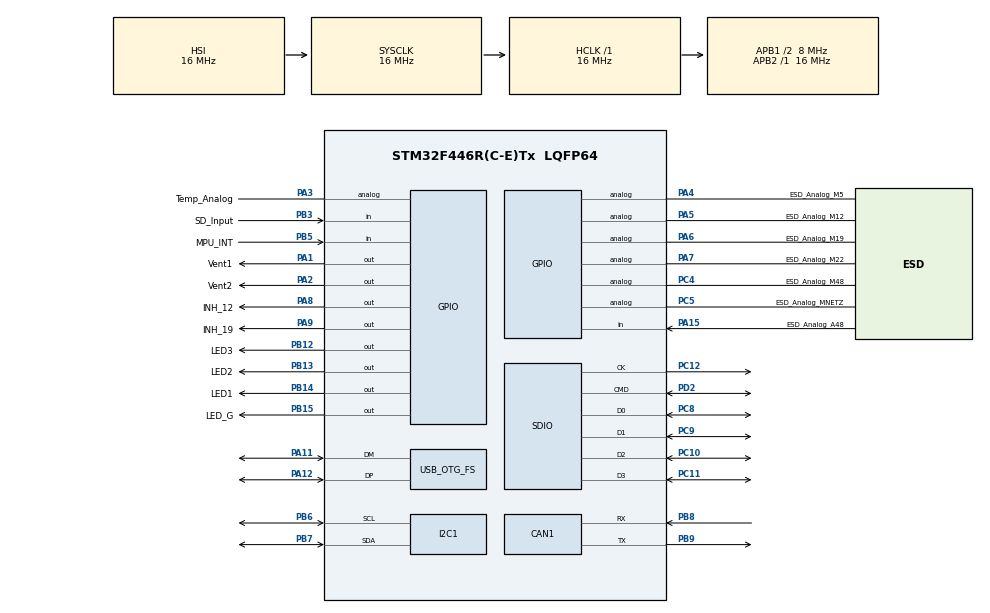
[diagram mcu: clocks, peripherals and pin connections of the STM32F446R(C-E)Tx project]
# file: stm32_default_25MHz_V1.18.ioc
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CAN1.CalculateTimeQuantum=2000.0
Mcu.Family=STM32F4
Mcu.Name=STM32F446R(C-E)Tx
Mcu.Package=LQFP64
NVIC.OTG_FS_IRQn=true\:0\:0\:false\:false\:true\:false\:true
NVIC.PriorityGroup=NVIC_PRIORITYGROUP_4
PA1.GPIO_Label=Vent1
PA1.Signal=GPIO_Output
PA11.Mode=Device_Only
PA11.Signal=USB_OTG_FS_DM
PA12.Mode=Device_Only
PA12.Signal=USB_OTG_FS_DP
PA13.Mode=Serial_Wire
PA13.Signal=SYS_JTMS-SWDIO
PA14.Mode=Serial_Wire
PA14.Signal=SYS_JTCK-SWCLK
PA15.GPIO_Label=ESD_Analog_A48
PA15.Signal=GPIO_Input
PA2.GPIO_Label=Vent2
PA2.Signal=GPIO_Output
PA3.GPIO_Label=Temp_Analog
PA3.Signal=GPIO_Analog
PA4.GPIO_Label=ESD_Analog_M5
PA4.Signal=GPIO_Analog
PA5.GPIO_Label=ESD_Analog_M12
PA5.Signal=GPIO_Analog
PA6.GPIO_Label=ESD_Analog_M19
PA6.Signal=GPIO_Analog
PA7.GPIO_Label=ESD_Analog_M22
PA7.Signal=GPIO_Analog
PA8.GPIO_Label=INH_12
PA8.Signal=GPIO_Output
PA9.GPIO_Label=INH_19
PA9.Signal=GPIO_Output
PB12.GPIO_Label=LED3
PB12.Signal=GPIO_Output
PB13.GPIO_Label=LED2
PB13.Signal=GPIO_Output
PB14.GPIO_Label=LED1
PB14.Signal=GPIO_Output
PB15.GPIO_Label=LED_G
PB15.Signal=GPIO_Output
PB3.GPIO_Label=SD_Input
PB3.Signal=GPIO_Input
PB5.GPIO_Label=MPU_INT
PB5.Signal=GPIO_Input
PB6.Mode=I2C
PB6.Signal=I2C1_SCL
PB7.Mode=I2C
PB7.Signal=I2C1_SDA
PB8.Mode=Master
PB8.Signal=CAN1_RX
PB9.Mode=Master
PB9.Signal=CAN1_TX
PC10.Mode=SD_4_bits_Wide_bus
PC10.Signal=SDIO_D2
PC11.Mode=SD_4_bits_Wide_bus
PC11.Signal=SDIO_D3
PC12.Mode=SD_4_bits_Wide_bus
PC12.Signal=SDIO_CK
PC4.GPIO_Label=ESD_Analog_M48
PC4.Signal=GPIO_Analog
PC5.GPIO_Label=ESD_Analog_MNETZ
PC5.Signal=GPIO_Analog
PC8.Mode=SD_4_bits_Wide_bus
PC8.Signal=SDIO_D0
PC9.Mode=SD_4_bits_Wide_bus
PC9.Signal=SDIO_D1
PD2.Mode=SD_4_bits_Wide_bus
PD2.Signal=SDIO_CMD
PH0-OSC_IN.Mode=HSE-External-Oscillator
PH0-OSC_IN.Signal=RCC_OSC_IN
PH1-OSC_OUT.Mode=HSE-External-Oscillator
PH1-OSC_OUT.Signal=RCC_OSC_OUT
ProjectManager.HeapSize=0x200
ProjectManager.StackSize=0x400
ProjectManager.TargetToolchain=TrueSTUDIO
RCC.AHBFreq_Value=16000000
RCC.APB1CLKDivider=RCC_HCLK_DIV2
RCC.APB1Freq_Value=8000000
RCC.APB1TimFreq_Value=16000000
RCC.APB2Freq_Value=16000000
RCC.APB2TimFreq_Value=16000000
RCC.CortexFreq_Value=16000000
RCC.HCLKFreq_Value=16000000
RCC.HSE_VALUE=25000000
RCC.PLLM=15
RCC.PLLN=144
RCC.PLLQ=5
RCC.SYSCLKFreq_VALUE=16000000
RCC.USBFreq_Value=48000000
RCC.VCOOutputFreq_Value=240000000
USB_DEVICE.CLASS_NAME_FS=CDC
USB_DEVICE.VirtualMode-CDC_FS=Cdc
USB_DEVICE.VirtualModeFS=Cdc_FS
USB_OTG_FS.VirtualMode=Device_Only
VP_USB_DEVICE_VS_USB_DEVICE_CDC_FS.Mode=CDC_FS
board=custom

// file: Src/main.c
/* USER CODE BEGIN Header */
/**
  ******************************************************************************
  * @file           : main.c
  * @brief          : Main program body
  ******************************************************************************
  * @attention
  *
  * <h2><center>&copy; Copyright (c) 2019 STMicroelectronics.
  * All rights reserved.</center></h2>
  *
  * This software component is licensed by ST under BSD 3-Clause license,
  * the "License"; You may not use this file except in compliance with the
  * License. You may obtain a copy of the License at:
  *                        opensource.org/licenses/BSD-3-Clause
  *
  ******************************************************************************
  */
/* USER CODE END Header */

#include "main.h"
#include "can.h"
#include "i2c.h"
#include "sdio.h"
#include "usb_device.h"
#include "gpio.h"

void SystemClock_Config(void);

int main(void)
{

  /* MCU Configuration--------------------------------------------------------*/

  /* Reset of all peripherals, Initializes the Flash interface and the Systick. */
  HAL_Init();

  /* Configure the system clock */
  SystemClock_Config();

  /* Initialize all configured peripherals */
  MX_GPIO_Init();
  MX_CAN1_Init();
  MX_I2C1_Init();
  MX_SDIO_SD_Init();
  MX_USB_DEVICE_Init();
  /* USER CODE BEGIN 2 */

  HAL_GPIO_WritePin(INH_12_GPIO_Port, INH_12_Pin, GPIO_PIN_RESET);
  HAL_GPIO_WritePin(INH_19_GPIO_Port, INH_19_Pin, GPIO_PIN_RESET);
  HAL_GPIO_WritePin(LED_G_GPIO_Port, LED_G_Pin, GPIO_PIN_SET);

  /* USER CODE END 2 */

  /* Infinite loop */
  while (1)
  {

  }
}

void SystemClock_Config(void)
{
  RCC_OscInitTypeDef RCC_OscInitStruct = {0};
  RCC_ClkInitTypeDef RCC_ClkInitStruct = {0};
  RCC_PeriphCLKInitTypeDef PeriphClkInitStruct = {0};

  /** Configure the main internal regulator output voltage
  */
  __HAL_RCC_PWR_CLK_ENABLE();
  __HAL_PWR_VOLTAGESCALING_CONFIG(PWR_REGULATOR_VOLTAGE_SCALE3);
  /** Initializes the CPU, AHB and APB busses clocks
  */
  RCC_OscInitStruct.OscillatorType = RCC_OSCILLATORTYPE_HSI;
  RCC_OscInitStruct.HSIState = RCC_HSI_ON;
  RCC_OscInitStruct.HSICalibrationValue = RCC_HSICALIBRATION_DEFAULT;
  RCC_OscInitStruct.PLL.PLLState = RCC_PLL_ON;
  RCC_OscInitStruct.PLL.PLLSource = RCC_PLLSOURCE_HSE;
  RCC_OscInitStruct.PLL.PLLM = 15;
  RCC_OscInitStruct.PLL.PLLN = 144;
  RCC_OscInitStruct.PLL.PLLP = RCC_PLLP_DIV2;
  RCC_OscInitStruct.PLL.PLLQ = 5;
  RCC_OscInitStruct.PLL.PLLR = 2;
  if (HAL_RCC_OscConfig(&RCC_OscInitStruct) != HAL_OK)
  {
    Error_Handler();
  }
  /** Initializes the CPU, AHB and APB busses clocks
  */
  RCC_ClkInitStruct.ClockType = RCC_CLOCKTYPE_HCLK|RCC_CLOCKTYPE_SYSCLK
                              |RCC_CLOCKTYPE_PCLK1|RCC_CLOCKTYPE_PCLK2;
  RCC_ClkInitStruct.SYSCLKSource = RCC_SYSCLKSOURCE_HSI;
  RCC_ClkInitStruct.AHBCLKDivider = RCC_SYSCLK_DIV1;
  RCC_ClkInitStruct.APB1CLKDivider = RCC_HCLK_DIV2;
  RCC_ClkInitStruct.APB2CLKDivider = RCC_HCLK_DIV1;

  if (HAL_RCC_ClockConfig(&RCC_ClkInitStruct, FLASH_LATENCY_0) != HAL_OK)
  {
    Error_Handler();
  }
  PeriphClkInitStruct.PeriphClockSelection = RCC_PERIPHCLK_SDIO|RCC_PERIPHCLK_CLK48;
  PeriphClkInitStruct.Clk48ClockSelection = RCC_CLK48CLKSOURCE_PLLQ;
  PeriphClkInitStruct.SdioClockSelection = RCC_SDIOCLKSOURCE_CLK48;
  if (HAL_RCCEx_PeriphCLKConfig(&PeriphClkInitStruct) != HAL_OK)
  {
    Error_Handler();
  }
}

void Error_Handler(void)
{
}

/************************ (C) COPYRIGHT STMicroelectronics *****END OF FILE****/
